VERSION ""

NS_ :

BS_:

BU_:

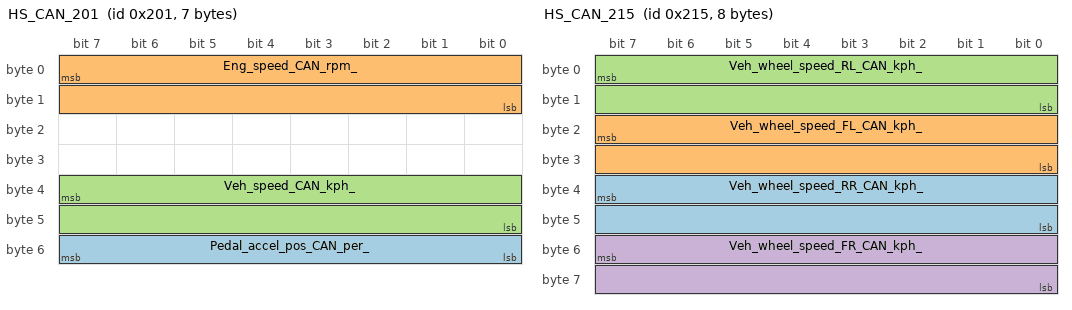
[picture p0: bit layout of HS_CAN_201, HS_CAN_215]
BO_ 513 HS_CAN_201: 7 Vector__XXX
 SG_ Pedal_accel_pos_CAN_per_ : 55|8@0+ (0.5,0) [0|127.5] "%" Vector__XXX
 SG_ Eng_speed_CAN_rpm_ : 7|16@0+ (0.25,0) [0|16383.75] "rpm" Vector__XXX
 SG_ Veh_speed_CAN_kph_ : 39|16@0+ (0.01,-100) [0|650] "kph" Vector__XXX

BO_ 560 HS_CAN_230: 1 Vector__XXX
 SG_ Trans_gear_actual_CAN_ : 3|3@0+ (1,0) [0|8] "" Vector__XXX

BO_ 533 HS_CAN_215: 8 Vector__XXX
 SG_ Veh_wheel_speed_RR_CAN_kph_ : 39|16@0+ (0.01,-100) [0|650] "kph" Vector__XXX
 SG_ Veh_wheel_speed_FL_CAN_kph_ : 23|16@0+ (0.01,-100) [0|650] "kph" Vector__XXX
 SG_ Veh_wheel_speed_RL_CAN_kph_ : 7|16@0+ (0.01,-100) [0|650] "kph" Vector__XXX
 SG_ Veh_wheel_speed_FR_CAN_kph_ : 55|16@0+ (0.01,-100) [0|650] "kph" Vector__XXX

BO_ 1072 HS_CAN_430: 8 Vector__XXX
 SG_ Fuel_level_CAN_per_ : 7|8@0+ (1,0.3921568627450981) [0|100.01] "%" Vector__XXX

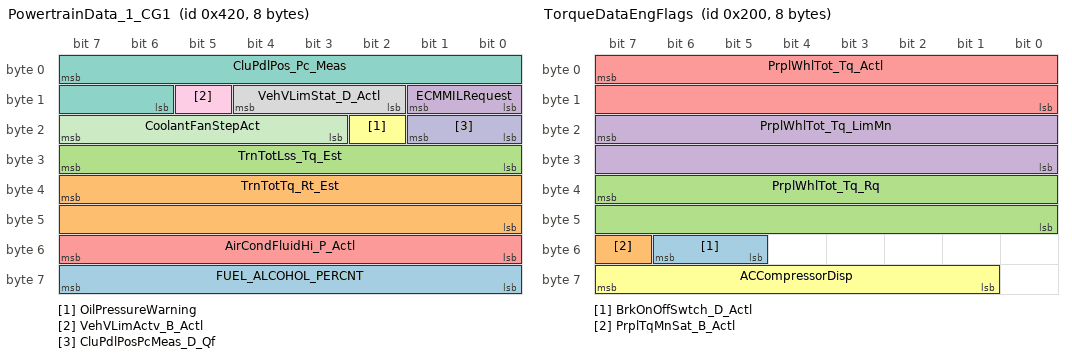
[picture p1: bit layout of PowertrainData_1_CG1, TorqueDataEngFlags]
BO_ 1056 PowertrainData_1_CG1: 8 XXX
 SG_ FUEL_ALCOHOL_PERCNT : 63|8@0+ (0.3937008,0) [0|100] "%" XXX
 SG_ TrnTotTq_Rt_Est : 39|16@0+ (0.001,0) [0|0] "" XXX
 SG_ TrnTotLss_Tq_Est : 31|8@0+ (0.5,0) [0|0] "Nm" XXX
 SG_ ECMMILRequest : 9|2@0+ (1,0) [0|0] "" XXX
 SG_ AirCondFluidHi_P_Actl : 55|8@0+ (0.125,0) [0|0] "bar" XXX
 SG_ OilPressureWarning : 18|1@0+ (1,0) [0|0] "" XXX
 SG_ CluPdlPos_Pc_Meas : 7|10@0+ (0.1,0) [0|0] "%" XXX
 SG_ VehVLimStat_D_Actl : 12|3@0+ (1,0) [0|0] "" XXX
 SG_ VehVLimActv_B_Actl : 13|1@0+ (1,0) [0|0] "" XXX
 SG_ CluPdlPosPcMeas_D_Qf : 17|2@0+ (1,0) [0|0] "" XXX
 SG_ CoolantFanStepAct : 23|5@0+ (1,0) [0|0] "Steps" XXX

BO_ 512 TorqueDataEngFlags: 8 XXX
 SG_ BrkOnOffSwtch_D_Actl : 54|2@0+ (1,0) [0|0] "" XXX
 SG_ PrplTqMnSat_B_Actl : 55|1@0+ (1,0) [0|0] "" XXX
 SG_ PrplWhlTot_Tq_Rq : 39|16@0+ (4.0,-131072.0) [0|0] "Nm" XXX
 SG_ PrplWhlTot_Tq_LimMn : 23|16@0+ (4.0,-131072.0) [0|0] "Nm" XXX
 SG_ PrplWhlTot_Tq_Actl : 7|16@0+ (4.0,-131072.0) [0|0] "Nm" XXX
 SG_ ACCompressorDisp : 63|7@0+ (1,0) [0|0] "%" XXX
